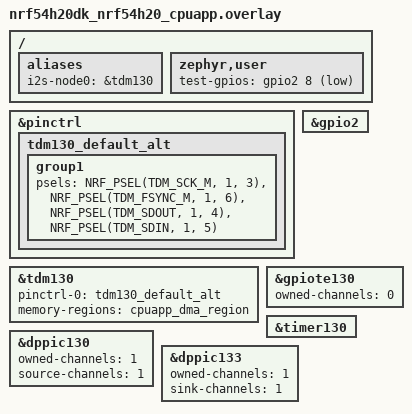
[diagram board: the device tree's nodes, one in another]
/*
 * Copyright (c) 2025 Nordic Semiconductor ASA
 *
 * SPDX-License-Identifier: LicenseRef-Nordic-5-Clause
 */

/* Test requires wire connection:
 *  - I2S_LRCK_M with test-gpios -> P1.06 - P2.08.
 */

/ {
	aliases {
		i2s-node0 = &tdm130;
	};
};

/ {
	zephyr,user {
		test-gpios = <&gpio2 8 GPIO_ACTIVE_LOW>;
	};
};

&pinctrl {
	tdm130_default_alt: tdm130_default_alt {
		group1 {
			psels = <NRF_PSEL(TDM_SCK_M, 1, 3)>,
				<NRF_PSEL(TDM_FSYNC_M, 1, 6)>,
				<NRF_PSEL(TDM_SDOUT, 1, 4)>,
				<NRF_PSEL(TDM_SDIN, 1, 5)>;
		};
	};
};

&gpio2 {
	status = "okay";
};

&tdm130 {
	status = "okay";
	pinctrl-0 = <&tdm130_default_alt>;
	pinctrl-names = "default";
	memory-regions = <&cpuapp_dma_region>;
};

&gpiote130 {
	owned-channels = <0>;
	status = "okay";
};

&timer130 {
	status = "okay";
};

&dppic130 {
	owned-channels = <1>;
	source-channels = <1>;
	status = "okay";
};

&dppic133 {
	owned-channels = <1>;
	sink-channels = <1>;
	status = "okay";
};
